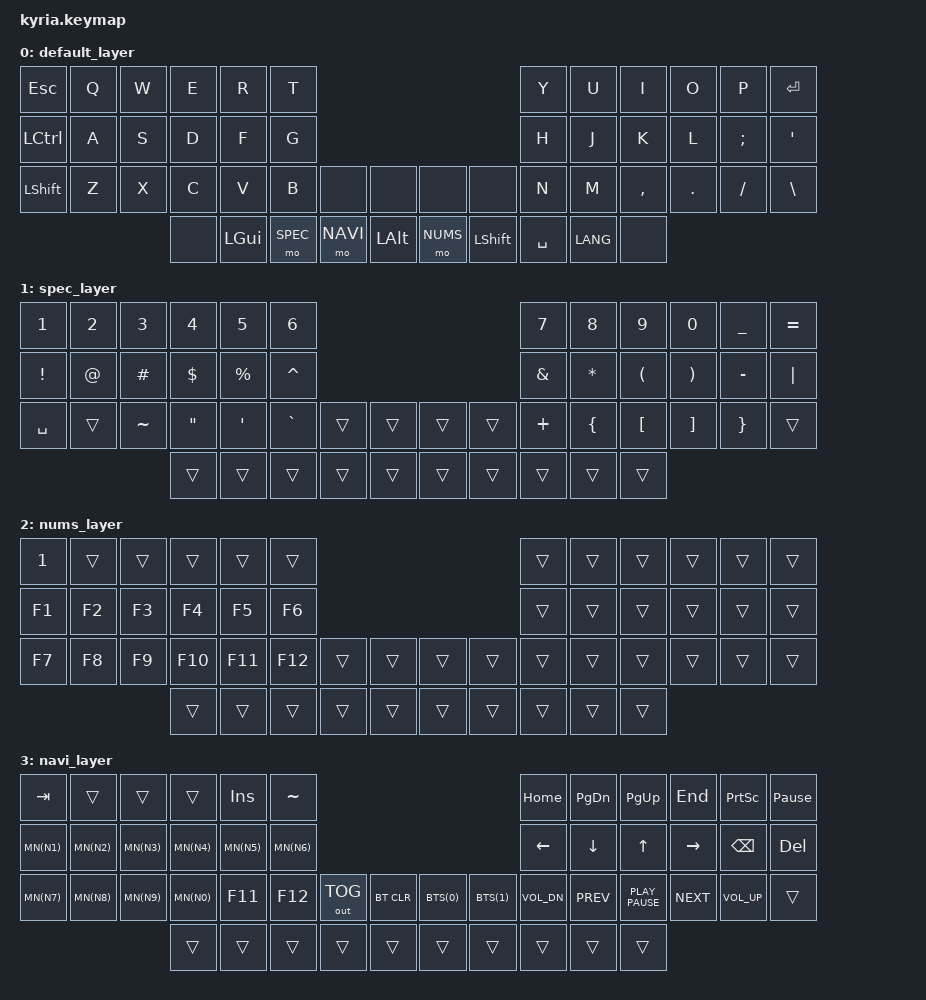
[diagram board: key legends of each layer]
/*
 * Copyright (c) 2020 The ZMK Contributors
 *
 * SPDX-License-Identifier: MIT
 */

#include <behaviors.dtsi>
#include <dt-bindings/zmk/keys.h>
#include <dt-bindings/zmk/bt.h>
#include <dt-bindings/zmk/outputs.h>
#include <dt-bindings/zmk/ext_power.h>

#define SPEC 1
#define NUMS 2
#define NAVI 3
#define LANG LG(SPACE)
#define BTS(n) &bt BT_SEL n
#define MN(n) &kp LG n



/ {
	chosen {
		zephyr,console = &cdc_acm_uart;
	};

	keymap {
		compatible = "zmk,keymap";

		default_layer {
// -----------------------------------------------------------------------------------------------------------
// | ESC   |  Q  |  W  |  E  |  R  |  T   |                             |  Y  |  U   |  I  |  O  |  P  | ENTER |
// | CTRL  |  A  |  S  |  D  |  F  |  G   |                             |  H  |  J   |  K  |  L  |  ;  |   '   |
// | SHIFT |  Z  |  X  |  C  |  V  |  B   |      |     | |      |       |  N  |  M   |  ,  |  .  |  /  |   \   |
//                     | ROT | GUI | SPEC | NAVI | ALT | | NUMS | SHIFT | SPC | LANG | ROT |
			bindings = <
&kp ESC   &kp Q  &kp W  &kp E  &kp R    &kp T                                            &kp Y     &kp U    &kp I     &kp O   &kp P     &kp ENTER
&kp LCTRL &kp A  &kp S  &kp D  &kp F    &kp G                                            &kp H     &kp J    &kp K     &kp L   &kp SEMI  &kp SQT
&kp LSHFT &kp Z  &kp X  &kp C  &kp V    &kp B    &none    &none     &none     &none      &kp N     &kp M    &kp COMMA &kp DOT &kp SLASH &kp BACKSLASH
                        &none  &kp LGUI &mo SPEC &mo NAVI &kp LALT  &mo NUMS  &kp LSHFT  &kp SPACE &kp LANG &none
			>;

			sensor-bindings = <&inc_dec_kp PG_UP PG_DN>;

		};

		spec_layer {
// ------------------------------------------------------------------------------------------------------
// |  1  |  2  |  3  |  4  |  5  |   6   |                      |   7   |   8   |  9  |  0  |  _  |  =  |
// |  !  |  @  |  #  |  $  |  %  |   ^   |                      |   &   |   *   |  (  |  )  |  -  |  |  |
// |     |     |  ~  |  "  |  '  |   `   |    |    |  |    |    |   +   |   {   |  [  |  ]  |  }  |     |
//                   |     |     |       |    |    |  |    |    |       |       |     |
			bindings = <
&kp N1    &kp N2  &kp N3    &kp N4     &kp N5    &kp N6                                  &kp N7    &kp N8    &kp N9    &kp N0    &kp UNDER  &kp EQUAL
&kp EXCL  &kp AT  &kp HASH  &kp DOLLAR &kp PRCNT &kp CARET                               &kp AMPS  &kp ASTRK &kp LPAR  &kp RPAR  &kp MINUS  &kp PIPE
&kp SPACE &trans  &kp TILDE &kp DQT    &kp SQT   &kp GRAVE &trans &trans   &trans &trans &kp PLUS  &kp LBRC  &kp LBKT  &kp RBKT  &kp RBRC   &trans
                            &trans     &trans    &trans    &trans &trans   &trans &trans &trans    &trans    &trans
			>;

			sensor-bindings = <&inc_dec_kp UP DOWN>;
		};

		nums_layer {
// ----------------------------------------------------------------------------------------------------
// |     |     |     |     |     |       |                      |       |       |     |     |     |     |
// |     |     |     |     |     |       |                      |       |       |     |     |     |     |
// |     |     |     |     |     |       |    |    |  |    |    |       |       |     |     |     |     |
//                   |     |     |       |    |    |  |    |    |       |       |     |
			bindings = <
&kp N1  &trans &trans &trans   &trans   &trans                                   &trans  &trans   &trans  &trans  &trans  &trans
&kp F1  &kp F2 &kp F3 &kp F4   &kp F5   &kp F6                                   &trans  &trans   &trans  &trans  &trans  &trans
&kp F7  &kp F8 &kp F9 &kp F10  &kp F11  &kp F12   &trans &trans   &trans &trans  &trans  &trans   &trans  &trans  &trans  &trans
                      &trans   &trans   &trans    &trans &trans   &trans &trans  &trans  &trans   &trans
			>;
		};

		navi_layer {
// ----------------------------------------------------------------------------------------------------
// | TAB  |     |     |      | INS |  ё  |                               | HOME  | PGDN | PGUP | END | PSCR|PAUSE|
// |META+1|     |     |      |     |     |                               | LEFT  | DOWN |  UP  |RIGHT|BKSPC| DEL |
// |      |     |     |META+0| F11 | F12 | BT CLR | OUT_T |  | BT1 | BT2 | VOLDN | PREV |  PP  | NEXT|VOLUP|     |
//                    |      |     |     |        |       |  |     |     |       |      |
			bindings = <
&kp TAB &trans &trans &trans   &kp INS  &kp TILDE                                       &kp HOME      &kp PG_DN  &kp PG_UP        &kp END    &kp PSCRN     &kp PAUSE_BREAK
MN(N1)  MN(N2) MN(N3) MN(N4)   MN(N5)   MN(N6)                                          &kp LEFT      &kp DOWN   &kp UP           &kp RIGHT  &kp BSPC      &kp DEL
MN(N7)  MN(N8) MN(N9) MN(N0)   &kp F11  &kp F12  &out OUT_TOG &bt BT_CLR   BTS(0) BTS(1) &kp C_VOL_DN  &kp K_PREV &kp K_PLAY_PAUSE &kp K_NEXT &kp C_VOL_UP  &trans
                      &trans   &trans   &trans   &trans       &trans       &trans &trans &trans        &trans     &trans
			>;

			sensor-bindings = <&inc_dec_kp C_VOL_UP C_VOL_DN>;
		};
	};
};

&usbd {
	status = "okay";
	cdc_acm_uart: cdc_acm_uart {
		compatible = "zephyr,cdc-acm-uart";
		label = "CDC_ACM_0";
	};
};
